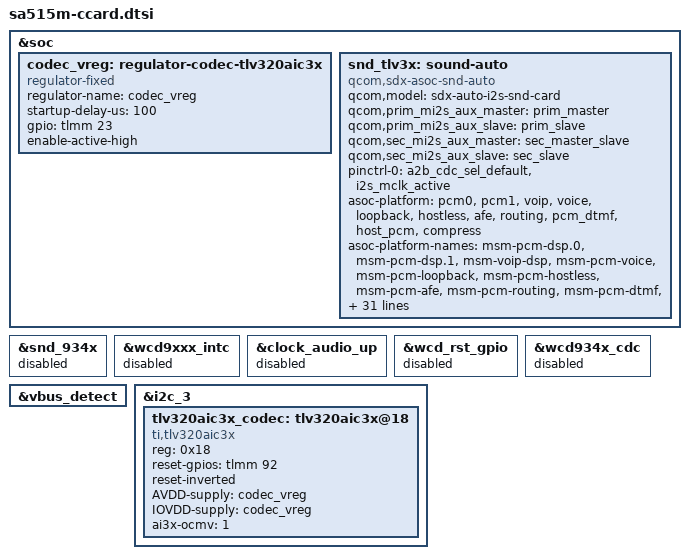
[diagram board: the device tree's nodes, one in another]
#include "sdx55-mtp.dtsi"
#include "sa515m-ccard-cnss.dtsi"

&soc {
	codec_vreg: regulator-codec-tlv320aic3x {
		compatible = "regulator-fixed";
		regulator-name = "codec_vreg";
		startup-delay-us = <100>;
		gpio = <&tlmm 23 GPIO_ACTIVE_HIGH>;
		enable-active-high;
	};

	snd_tlv3x: sound-auto {
		compatible = "qcom,sdx-asoc-snd-auto";
		qcom,model = "sdx-auto-i2s-snd-card";
		qcom,prim_mi2s_aux_master = <&prim_master>;
		qcom,prim_mi2s_aux_slave = <&prim_slave>;
		qcom,sec_mi2s_aux_master = <&sec_master_slave>;
		qcom,sec_mi2s_aux_slave = <&sec_slave>;

		pinctrl-names = "default";
		pinctrl-0 = <&a2b_cdc_sel_default>, <&i2s_mclk_active>;

		asoc-platform = <&pcm0>, <&pcm1>, <&voip>, <&voice>,
				<&loopback>, <&hostless>, <&afe>, <&routing>,
				<&pcm_dtmf>, <&host_pcm>, <&compress>;
		asoc-platform-names = "msm-pcm-dsp.0", "msm-pcm-dsp.1",
				"msm-voip-dsp", "msm-pcm-voice",
				"msm-pcm-loopback", "msm-pcm-hostless",
				"msm-pcm-afe", "msm-pcm-routing",
				"msm-pcm-dtmf", "msm-voice-host-pcm",
				"msm-compress-dsp";
		asoc-cpu = <&dai_pri_auxpcm>, <&mi2s_prim>, <&mi2s_sec>,
				<&dtmf_tx>,
				<&rx_capture_tx>, <&rx_playback_rx>,
				<&tx_capture_tx>, <&tx_playback_rx>,
				<&afe_pcm_rx>, <&afe_pcm_tx>, <&afe_proxy_rx>,
				<&afe_proxy_tx>, <&incall_record_rx>,
				<&incall_record_tx>, <&incall_music_rx>,
				<&dai_pri_tdm_rx_0>, <&dai_pri_tdm_tx_0>,
				<&dai_pri_tdm_rx_1>, <&dai_pri_tdm_tx_1>,
				<&dai_sec_tdm_rx_0>, <&dai_sec_tdm_tx_0>,
				<&dai_sec_tdm_rx_1>, <&dai_sec_tdm_tx_1>,
				<&dai_sec_auxpcm>, <&incall2_record_rx>,
				<&incall_music_2_rx>, <&incall_music_dl_rx>;
		asoc-cpu-names = "msm-dai-q6-auxpcm.1",
				"msm-dai-q6-mi2s.0", "msm-dai-q6-mi2s.1",
				"msm-dai-stub-dev.4", "msm-dai-stub-dev.5",
				"msm-dai-stub-dev.6", "msm-dai-stub-dev.7",
				"msm-dai-stub-dev.8", "msm-dai-q6-dev.224",
				"msm-dai-q6-dev.225", "msm-dai-q6-dev.241",
				"msm-dai-q6-dev.240", "msm-dai-q6-dev.32771",
				"msm-dai-q6-dev.32772", "msm-dai-q6-dev.32773",
				"msm-dai-q6-tdm.36864", "msm-dai-q6-tdm.36865",
				"msm-dai-q6-tdm.36866", "msm-dai-q6-tdm.36867",
				"msm-dai-q6-tdm.36880", "msm-dai-q6-tdm.36881",
				"msm-dai-q6-tdm.36882", "msm-dai-q6-tdm.36883",
				"msm-dai-q6-auxpcm.2", "msm-dai-q6-dev.32769",
				"msm-dai-q6-dev.32770", "msm-dai-q6-dev.32774";
		asoc-codec = <&tlv320aic3x_codec>, <&stub_codec>;
		asoc-codec-names = "tlv320aic3x-codec", "msm-stub-codec.1";
		qcom,msm_audio_ssr_devs = <&audio_apr>, <&q6core>;
	};

};

&snd_934x {
	status = "disabled";
};

&wcd9xxx_intc {
	status = "disabled";
};

&clock_audio_up {
	status = "disabled";
};

&wcd_rst_gpio {
	status = "disabled";
};

&wcd934x_cdc {
	status = "disabled";
};

&vbus_detect {
	status = "okay";
};

&i2c_3 {
	tlv320aic3x_codec: tlv320aic3x@18 {
		compatible = "ti,tlv320aic3x";
		reg = <0x18>;
		reset-gpios = <&tlmm 92 0>;
		reset-inverted;
		AVDD-supply = <&codec_vreg>;
		IOVDD-supply = <&codec_vreg>;
		ai3x-ocmv = <1>;
	};
};

